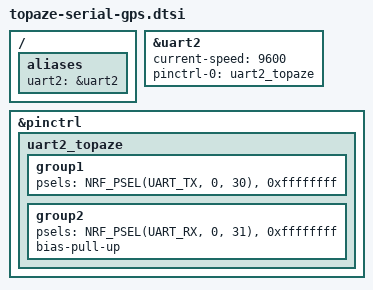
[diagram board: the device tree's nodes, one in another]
/* ============================================================
 * This file is the overlay DTS for topaze that define the UARTS
 *
 * We describe here the peripherals configuration, and so on...
 *
 * l.heywang
 * 01/03/2025
 *
 * ============================================================
 */

// ============================================================
// UARTS and PINCTRL
// ============================================================
// Enable UART drivers with defined settings
&uart2 {
    status = "okay";
    current-speed = <9600>;
    pinctrl-0 = <&uart2_topaze>;
    pinctrl-names = "default";
};

// UART for GPS. No flow control.
// On the DK, exposed pins to an header.
&pinctrl {
    uart2_topaze: uart2_topaze {
        group1 {
            psels = <NRF_PSEL(UART_TX, 0, 30)>,
                    <0xffffffff>; // RTS: Value for unused pin.
                };
        group2 {
            psels = <NRF_PSEL(UART_RX, 0, 31)>,
                    <0xffffffff>; // CTS: Value for unused pin.
                    bias-pull-up;
        };
    };
};

// Configure the console output as UART0 and
// set aliases for this module
/ {
    aliases {
        uart2 = &uart2;
    };
};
